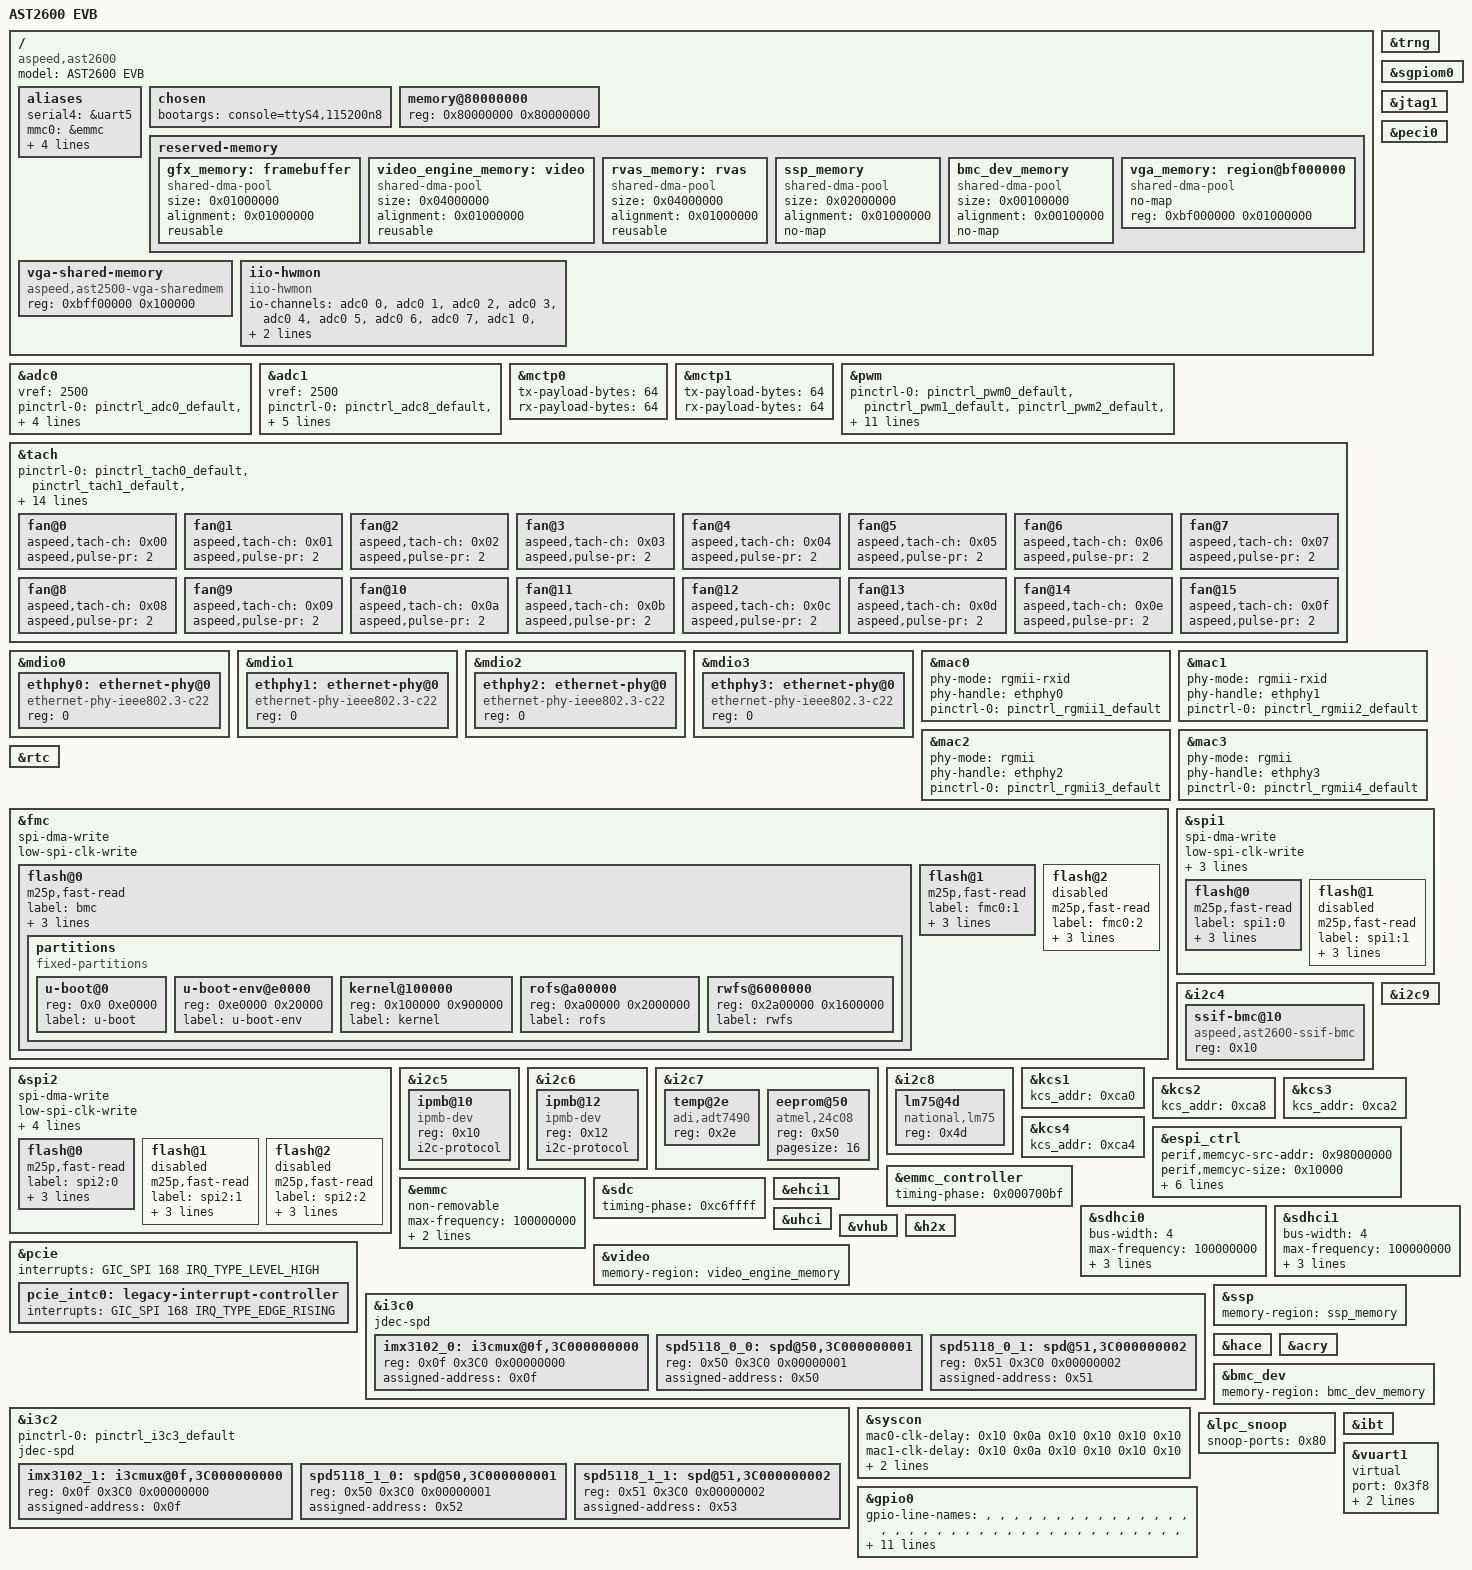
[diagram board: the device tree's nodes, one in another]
// SPDX-License-Identifier: GPL-2.0-or-later
// Copyright 2019 IBM Corp.

/dts-v1/;

#include "aspeed-g6.dtsi"

/ {
	model = "AST2600 EVB";
	compatible = "aspeed,ast2600";

	aliases {
		serial4 = &uart5;
		mmc0 = &emmc;
		mmc1 = &sdhci0;
		mmc2 = &sdhci1;
		mctp0 = &mctp0;
		mctp1 = &mctp1;
	};

	chosen {
		bootargs = "console=ttyS4,115200n8";
	};

	memory@80000000 {
		device_type = "memory";
		reg = <0x80000000 0x80000000>;
	};

	reserved-memory {
		#address-cells = <1>;
		#size-cells = <1>;
		ranges;

		gfx_memory: framebuffer {
			size = <0x01000000>;
			alignment = <0x01000000>;
			compatible = "shared-dma-pool";
			reusable;
		};

		video_engine_memory: video {
			size = <0x04000000>;
			alignment = <0x01000000>;
			compatible = "shared-dma-pool";
			reusable;
		};

		rvas_memory: rvas {
			size = <0x04000000>;
			alignment = <0x01000000>;
			compatible = "shared-dma-pool";
			reusable;
		};

		ssp_memory: ssp_memory {
			size = <0x02000000>;
			alignment = <0x01000000>;
			compatible = "shared-dma-pool";
			no-map;
		};

		bmc_dev_memory: bmc_dev_memory {
			size = <0x00100000>;
			alignment = <0x00100000>;
			compatible = "shared-dma-pool";
			no-map;
		};

		/* 1GB memory */
		vga_memory: region@bf000000 {
			no-map;
			compatible = "shared-dma-pool";
			reg = <0xbf000000 0x01000000>;  /* 16M */
		};

	};

	vga-shared-memory {
		compatible = "aspeed,ast2500-vga-sharedmem";
		reg = <0xbff00000 0x100000>;
	};

	iio-hwmon {
		compatible = "iio-hwmon";
		io-channels = <&adc0 0>, <&adc0 1>, <&adc0 2>, <&adc0 3>,
				<&adc0 4>, <&adc0 5>, <&adc0 6>, <&adc0 7>,
				<&adc1 0>, <&adc1 1>, <&adc1 2>, <&adc1 3>,
				<&adc1 4>, <&adc1 5>, <&adc1 6>, <&adc1 7>;
	};

};

&trng {
	status = "okay";
};

&adc0 {
	vref = <2500>;
	status = "okay";

	pinctrl-names = "default";
	pinctrl-0 = <&pinctrl_adc0_default &pinctrl_adc1_default
		&pinctrl_adc2_default &pinctrl_adc3_default
		&pinctrl_adc4_default &pinctrl_adc5_default
		&pinctrl_adc6_default &pinctrl_adc7_default>;
};

&adc1 {
	vref = <2500>;
	status = "okay";

	pinctrl-names = "default";
	pinctrl-0 = <&pinctrl_adc8_default &pinctrl_adc9_default
		&pinctrl_adc10_default &pinctrl_adc11_default
		&pinctrl_adc12_default &pinctrl_adc13_default
		&pinctrl_adc14_default &pinctrl_adc15_default>;
};

&mctp0 {
	tx-payload-bytes= <64>;
	rx-payload-bytes= <64>;
	status = "okay";
};

&mctp1 {
	tx-payload-bytes= <64>;
	rx-payload-bytes= <64>;
	status = "okay";
};

&sgpiom0 {
	status = "okay";
};

&jtag1 {
	status = "okay";
};

&peci0 {
	status = "okay";
};

&pwm {
	status = "okay";
	pinctrl-names = "default";
	pinctrl-0 = <&pinctrl_pwm0_default
			&pinctrl_pwm1_default
			&pinctrl_pwm2_default
			&pinctrl_pwm3_default
			&pinctrl_pwm4_default
			&pinctrl_pwm5_default
			&pinctrl_pwm6_default
			&pinctrl_pwm7_default
			&pinctrl_pwm8g1_default
			&pinctrl_pwm9g1_default
			&pinctrl_pwm10g1_default
			&pinctrl_pwm11g1_default
			&pinctrl_pwm12g1_default
			&pinctrl_pwm13g1_default
			&pinctrl_pwm14g1_default
			&pinctrl_pwm15g1_default>;
};

&tach {
	status = "okay";
	pinctrl-names = "default";
	pinctrl-0 = <&pinctrl_tach0_default
			&pinctrl_tach1_default
			&pinctrl_tach2_default
			&pinctrl_tach3_default
			&pinctrl_tach4_default
			&pinctrl_tach5_default
			&pinctrl_tach6_default
			&pinctrl_tach7_default
			&pinctrl_tach8_default
			&pinctrl_tach9_default
			&pinctrl_tach10_default
			&pinctrl_tach11_default
			&pinctrl_tach12_default
			&pinctrl_tach13_default
			&pinctrl_tach14_default
			&pinctrl_tach15_default>;
	fan@0 {
		aspeed,tach-ch = <0x00>;
		aspeed,pulse-pr = <2>;
	};

	fan@1 {
		aspeed,tach-ch = <0x01>;
		aspeed,pulse-pr = <2>;
	};

	fan@2 {
		aspeed,tach-ch = <0x02>;
		aspeed,pulse-pr = <2>;
	};

	fan@3 {
		aspeed,tach-ch = <0x03>;
		aspeed,pulse-pr = <2>;
	};

	fan@4 {
		aspeed,tach-ch = <0x04>;
		aspeed,pulse-pr = <2>;
	};

	fan@5 {
		aspeed,tach-ch = <0x05>;
		aspeed,pulse-pr = <2>;
	};

	fan@6 {
		aspeed,tach-ch = <0x06>;
		aspeed,pulse-pr = <2>;
	};

	fan@7 {
		aspeed,tach-ch = <0x07>;
		aspeed,pulse-pr = <2>;
	};

	fan@8 {
		aspeed,tach-ch = <0x08>;
		aspeed,pulse-pr = <2>;
	};

	fan@9 {
		aspeed,tach-ch = <0x09>;
		aspeed,pulse-pr = <2>;
	};

	fan@10 {
		aspeed,tach-ch = <0x0a>;
		aspeed,pulse-pr = <2>;
	};

	fan@11 {
		aspeed,tach-ch = <0x0b>;
		aspeed,pulse-pr = <2>;
	};

	fan@12 {
		aspeed,tach-ch = <0x0c>;
		aspeed,pulse-pr = <2>;
	};

	fan@13 {
		aspeed,tach-ch = <0x0d>;
		aspeed,pulse-pr = <2>;
	};

	fan@14 {
		aspeed,tach-ch = <0x0e>;
		aspeed,pulse-pr = <2>;
	};

	fan@15 {
		aspeed,tach-ch = <0x0f>;
		aspeed,pulse-pr = <2>;
	};
};

&mdio0 {
	status = "okay";

	ethphy0: ethernet-phy@0 {
		compatible = "ethernet-phy-ieee802.3-c22";
		reg = <0>;
	};
};

&mdio1 {
	status = "okay";

	ethphy1: ethernet-phy@0 {
		compatible = "ethernet-phy-ieee802.3-c22";
		reg = <0>;
	};
};

&mdio2 {
	status = "okay";

	ethphy2: ethernet-phy@0 {
		compatible = "ethernet-phy-ieee802.3-c22";
		reg = <0>;
	};
};

&mdio3 {
	status = "okay";

	ethphy3: ethernet-phy@0 {
		compatible = "ethernet-phy-ieee802.3-c22";
		reg = <0>;
	};
};

&mac0 {
	status = "okay";

	phy-mode = "rgmii-rxid";
	phy-handle = <&ethphy0>;

	pinctrl-names = "default";
	pinctrl-0 = <&pinctrl_rgmii1_default>;
};

&mac1 {
	status = "okay";

	phy-mode = "rgmii-rxid";
	phy-handle = <&ethphy1>;

	pinctrl-names = "default";
	pinctrl-0 = <&pinctrl_rgmii2_default>;
};

&mac2 {
	status = "okay";

	phy-mode = "rgmii";
	phy-handle = <&ethphy2>;

	pinctrl-names = "default";
	pinctrl-0 = <&pinctrl_rgmii3_default>;
};

&mac3 {
	status = "okay";

	phy-mode = "rgmii";
	phy-handle = <&ethphy3>;

	pinctrl-names = "default";
	pinctrl-0 = <&pinctrl_rgmii4_default>;
};

&rtc {
	status = "okay";
};

#if 1
&fmc {
	spi-dma-write;
	low-spi-clk-write;
	status = "okay";

	flash@0 {
		status = "okay";
		m25p,fast-read;
		label = "bmc";
		spi-max-frequency = <50000000>;
		spi-tx-bus-width = <1>;
		spi-rx-bus-width = <4>;
		partitions {
			compatible = "fixed-partitions";
			#address-cells = <1>;
			#size-cells = <1>;

			u-boot@0 {
				reg = <0x0 0xe0000>;
				label = "u-boot";
			};

			u-boot-env@e0000 {
				reg = <0xe0000 0x20000>; // 128KB
				label = "u-boot-env";
			};

			kernel@100000 {
				reg = <0x100000 0x900000>; // 9MB
				label = "kernel";
			};

			rofs@a00000 {
				reg = <0xa00000 0x2000000>; // 32MB
				label = "rofs";
			};

			rwfs@6000000 {
				reg = <0x2a00000 0x1600000>; // 22MB
				label = "rwfs";
			};

		};
	};

	flash@1 {
		status = "okay";
		m25p,fast-read;
		label = "fmc0:1";
		spi-max-frequency = <50000000>;
		spi-tx-bus-width = <1>;
		spi-rx-bus-width = <4>;
	};

	flash@2 {
		status = "disabled";
		m25p,fast-read;
		label = "fmc0:2";
		spi-max-frequency = <50000000>;
		spi-tx-bus-width = <1>;
		spi-rx-bus-width = <4>;
	};
};

#else

&fmc {
	status = "okay";
	flash@0 {
		status = "okay";
		compatible = "mx25l25635e", "m25p80", "jedec,spi-nor";
		reg = <0>;
		#address-cells = <0x1>;
		#size-cells = <0x1>;
		spi-max-frequency = <50000000>;
		m25p,fast-read;
		partition@0 {
			label = "all.bin 8MB";
			reg = <0x000000 0x0800000>; /* 8 MiB */
		};
		partition@1 {
			label = "u-boot";
			reg = <0x000000 0x060000>; /* 384 KiB */
		};
		partition@2 {
			label = "u-boot-env";
			reg = <0x060000 0x010000>; /* 64 KiB */
		};
		partition@3 {
			label = "dts";
			reg = <0x070000 0x010000>; /* 64 Kib */
		};
		partition@4 {
			label = "kernel";
			reg = <0x080000 0x380000>; /* 3.5 MiB */
		};
		partition@5 {
			label = "rootfs";
			reg = <0x400000 0x400000>; /* 4 MiB */
		};
		partition@6 {
			label = "pd_rootfs";
			reg = <0x800000 0x0>;
		};
	};

	flash@1 {
		status = "okay";
		m25p,fast-read;
		label = "fmc0:1";
		spi-max-frequency = <50000000>;
		spi-bus-width = <4>;
	};

	flash@2 {
		status = "disabled";
		m25p,fast-read;
		label = "fmc0:2";
		spi-max-frequency = <50000000>;
		spi-bus-width = <4>;
	};
};

#endif

&spi1 {
	spi-dma-write;
	low-spi-clk-write;
	pinctrl-names = "default";
	pinctrl-0 = <&pinctrl_spi1_default &pinctrl_spi1cs1_default
				&pinctrl_qspi1_default>;
	status = "okay";

	flash@0 {
		status = "okay";
		m25p,fast-read;
		label = "spi1:0";
		spi-max-frequency = <50000000>;
		spi-tx-bus-width = <1>;
		spi-rx-bus-width = <4>;
	};

	flash@1 {
		status = "disabled";
		m25p,fast-read;
		label = "spi1:1";
		spi-max-frequency = <50000000>;
		spi-tx-bus-width = <1>;
		spi-rx-bus-width = <4>;
	};
};

&spi2 {
	spi-dma-write;
	low-spi-clk-write;
	pinctrl-names = "default";
	pinctrl-0 = <&pinctrl_spi2_default &pinctrl_spi2cs1_default
				&pinctrl_spi2cs2_default &pinctrl_qspi2_default>;
	status = "okay";

	flash@0 {
		status = "okay";
		m25p,fast-read;
		label = "spi2:0";
		spi-max-frequency = <50000000>;
		spi-tx-bus-width = <1>;
		spi-rx-bus-width = <4>;
	};

	flash@1 {
		status = "disabled";
		m25p,fast-read;
		label = "spi2:1";
		spi-max-frequency = <50000000>;
		spi-tx-bus-width = <1>;
		spi-rx-bus-width = <4>;
	};

	flash@2 {
		status = "disabled";
		m25p,fast-read;
		label = "spi2:2";
		spi-max-frequency = <50000000>;
		spi-tx-bus-width = <1>;
		spi-rx-bus-width = <4>;
	};

};

&i2c4 {
	status = "okay";

	ssif-bmc@10 {
		compatible = "aspeed,ast2600-ssif-bmc";
		reg = <0x10>;
	};
};

&i2c5 {
	status = "okay";

	ipmb@10 {
		compatible = "ipmb-dev";
		reg = <0x10>;
		i2c-protocol;
	};
};

&i2c6 {
	status = "okay";

	ipmb@12 {
		compatible = "ipmb-dev";
		reg = <0x12>;
		i2c-protocol;
	};
};

&i2c7 {
	status = "okay";

	temp@2e {
		compatible = "adi,adt7490";
		reg = <0x2e>;
	};

	eeprom@50 {
		compatible = "atmel,24c08";
		reg = <0x50>;
		pagesize = <16>;
	};

};

&i2c8 {
	status = "okay";

	lm75@4d {
		compatible = "national,lm75";
		reg = <0x4d>;
	};

};

&i2c9 {
	status = "okay";
};

&kcs1 {
	kcs_addr = <0xca0>;
	status = "okay";
};

&kcs2 {
	kcs_addr = <0xca8>;
	status = "okay";
};

&kcs3 {
	kcs_addr = <0xca2>;
	status = "okay";
};

&kcs4 {
	kcs_addr = <0xca4>;
	status = "okay";
};

&espi_ctrl {
	status = "okay";

	perif,memcyc-src-addr = <0x98000000>;
	perif,memcyc-size = <0x10000>;
	perif,dma-mode;

	oob,dma-mode;
	oob,dma-tx-desc-num = <0x2>;
	oob,dma-rx-desc-num = <0x8>;

	flash,dma-mode;
	flash,safs-mode = <0x2>;
};

&emmc_controller {
	status = "okay";
	timing-phase = <0x000700bf>;
};

&emmc {
	status = "okay";

	non-removable;
	max-frequency = <100000000>;
	sdhci-drive-type = /bits/ 8 <3>;
#if 1
	bus-width = <4>;
#else
	bus-width = <8>;
	pinctrl-0 = <&pinctrl_emmc_default
			&pinctrl_emmcg8_default>;
#endif
};

&sdc {
	status = "okay";
	timing-phase = <0xc6ffff>;
};

&sdhci0 {
	status = "okay";

	bus-width = <4>;
	max-frequency = <100000000>;
	sdhci-drive-type = /bits/ 8 <3>;
	/* SDR104/DDR50/SDR50 bits in CAPA2 is not supported */
	sdhci-caps-mask = <0x7 0x0>;
	sdhci,wp-inverted;
};

&sdhci1 {
	status = "okay";

	bus-width = <4>;
	max-frequency = <100000000>;
	sdhci-drive-type = /bits/ 8 <3>;
	sdhci-caps-mask = <0x7 0x0>;
	sdhci,wp-inverted;
};

#if 0
&ehci0 {
	status = "okay";
};
#endif

&ehci1 {
	status = "okay";
};

&uhci {
	status = "okay";
};

&vhub {
	status = "okay";
	pinctrl-names = "default";
#if 0
	pinctrl-0 = <&pinctrl_usb2adp_default>;
#endif
};

#if 0
&udc {
	status = "okay";
	pinctrl-names = "default";
	pinctrl-0 = <&pinctrl_usb2bd_default>;
};
#endif

#if 0
&gfx {
	status = "okay";
	memory-region = <&gfx_memory>;
};

#endif

&pcie {
	status = "okay";

	interrupts = <GIC_SPI 168 IRQ_TYPE_LEVEL_HIGH>;

	pcie_intc0: legacy-interrupt-controller {
		interrupts = <GIC_SPI 168 IRQ_TYPE_EDGE_RISING>;
	};
};

&h2x {
	status = "okay";
};

#if 1
&video {
	status = "okay";
	memory-region = <&video_engine_memory>;
};
#else
&rvas {
	status = "okay";
	memory-region = <&rvas_memory>;
};
#endif

&i3c0 {
	status = "okay";
	jdec-spd;
	/* IDT IMX3102 multiplexer w/ thermal sensor */
	imx3102_0: i3cmux@0f,3C000000000 {
		reg = <0x0f 0x3C0 0x00000000>;
		assigned-address = <0x0f>;
	};

	/* Renesas SPD5118 */
	spd5118_0_0: spd@50,3C000000001 {
		reg = <0x50 0x3C0 0x00000001>;
		assigned-address = <0x50>;
	};

	/* Renesas SPD5118 */
	spd5118_0_1: spd@51,3C000000002 {
		reg = <0x51 0x3C0 0x00000002>;
		assigned-address = <0x51>;
	};
};

&i3c2 {
	status = "okay";
	pinctrl-names = "default";
	pinctrl-0 = <&pinctrl_i3c3_default>;

	jdec-spd;
	/* IDT IMX3102 multiplexer w/ thermal sensor */
	imx3102_1: i3cmux@0f,3C000000000 {
		reg = <0x0f 0x3C0 0x00000000>;
		assigned-address = <0x0f>;
	};

	/* Renesas SPD5118 */
	spd5118_1_0: spd@50,3C000000001 {
		reg = <0x50 0x3C0 0x00000001>;
		assigned-address = <0x52>;
	};

	/* Renesas SPD5118 */
	spd5118_1_1: spd@51,3C000000002 {
		reg = <0x51 0x3C0 0x00000002>;
		assigned-address = <0x53>;
	};
};

&syscon {
	mac0-clk-delay = <0x10 0x0a
			  0x10 0x10
			  0x10 0x10>;
	mac1-clk-delay = <0x10 0x0a
			  0x10 0x10
			  0x10 0x10>;
	mac2-clk-delay = <0x08 0x04
			  0x08 0x04
			  0x08 0x04>;
	mac3-clk-delay = <0x08 0x04
			  0x08 0x04
			  0x08 0x04>;
};

&ssp {
	memory-region = <&ssp_memory>;
};

&hace {
	status = "okay";
};

&acry {
	status = "okay";
};

&bmc_dev {
	status = "okay";
	memory-region = <&bmc_dev_memory>;
};

#if 0
&xdma {
	status = "okay";
	memory-region = <&vga_memory>;
};
#endif

&lpc_snoop {
	status = "okay";
	snoop-ports = <0x80>;
};

&ibt {
	status = "okay";
};

&vuart1 {
	virtual;
	port = <0x3f8>;
	sirq = <4>;
	sirq-polarity = <1>;
	status = "okay";
};

&gpio0 {
	gpio-line-names =
	/*A0 - A7*/	"", "", "", "", "", "", "", "",
	/*B0 - B7*/	"", "", "", "", "", "", "", "",
	/*C0 - C7*/	"", "", "", "", "", "", "", "",
	/*D0 - D7*/	"", "", "", "", "", "", "", "",
	/*E0 - E7*/	"", "", "", "", "", "", "", "",
	/*F0 - F7*/	"", "", "", "", "", "", "", "",
	/*G0 - G7*/	"", "", "", "", "", "", "", "",
	/*H0 - H7*/	"", "", "", "", "", "", "", "",
	/*I0 - I7*/	"", "", "", "", "", "RESET_OUT", "POST_COMPLETE", "POWER_OUT",
	/*J0 - J7*/	"", "", "", "", "", "", "", "",
	/*K0 - K7*/	"", "", "", "", "", "", "", "",
	/*L0 - L7*/	"", "", "", "", "", "", "", "",
	/*M0 - M7*/	"", "", "", "", "", "", "", "",
	/*N0 - N7*/	"", "", "", "", "", "", "", "",
	/*O0 - O7*/	"", "", "", "", "", "", "", "",
	/*P0 - P7*/	"", "", "", "", "", "", "", "",
	/*Q0 - Q7*/	"", "", "", "", "", "", "", "",
	/*R0 - R7*/	"", "", "", "", "", "", "", "",
	/*S0 - S7*/	"", "", "", "", "", "", "", "",
	/*T0 - T7*/	"", "", "", "", "", "", "", "",
	/*U0 - U7*/	"", "", "", "", "", "", "", "",
	/*V0 - V7*/	"", "", "", "", "PS_PWROK", "RESET_BUTTON", "POWER_BUTTON", "",
	/*W0 - W7*/	"", "", "", "", "", "", "", "",
	/*X0 - X7*/	"", "", "", "", "", "", "", "",
	/*Y0 - Y7*/	"", "", "", "", "", "", "", "",
	/*Z0 - Z7*/	"", "", "", "", "", "", "", "",
	/*AA0 - AA7*/	"", "", "", "", "", "", "", "",
	/*AB0 - AB7*/	"", "", "", "", "", "", "", "",
	/*AC0 - AC7*/	"", "", "", "", "", "", "", "";
};
